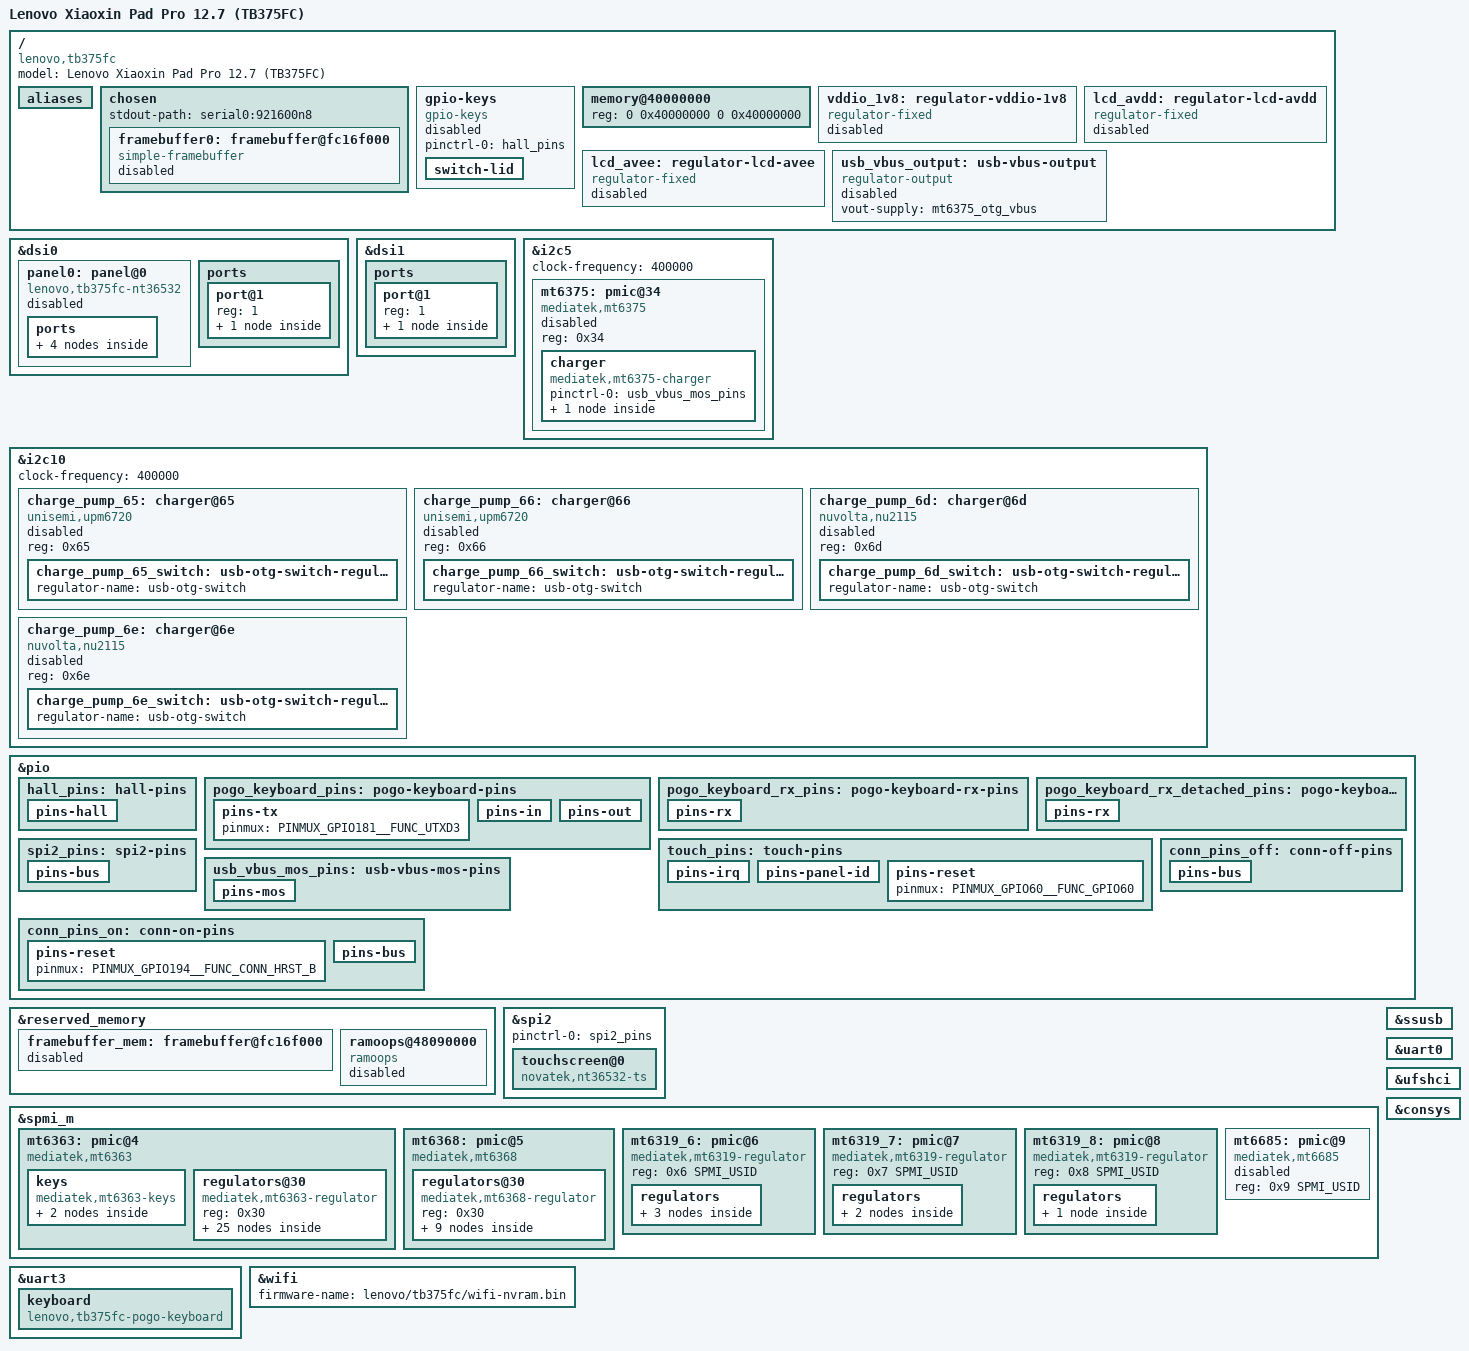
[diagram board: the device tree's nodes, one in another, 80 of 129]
// SPDX-License-Identifier: (GPL-2.0-only OR BSD-2-Clause)
/*
 * Lenovo Xiaoxin Pad Pro 12.7 (2025, TB375FC)
 *
 * Copyright (c) 2026 buntOS contributors
 */

/dts-v1/;
#include <dt-bindings/gpio/gpio.h>
#include <dt-bindings/input/input.h>
#include <dt-bindings/interrupt-controller/irq.h>
#include <dt-bindings/spmi/spmi.h>
#include "mt6897.dtsi"
#include "mt6897-pinfunc.h"

/ {
	model = "Lenovo Xiaoxin Pad Pro 12.7 (TB375FC)";
	compatible = "lenovo,tb375fc", "mediatek,mt6897";

	aliases {
		i2c5 = &i2c5;
		i2c10 = &i2c10;
		serial0 = &uart0;
		spmi0 = &spmi_m;
	};

	chosen {
		#address-cells = <2>;
		#size-cells = <2>;
		ranges;

		stdout-path = "serial0:921600n8";

		/*
		 * The bootloader drives the panel over both DSI links with DSC
		 * and scans out one 2944x1840 buffer. TODO(2a): the base is
		 * from the community port's bootloader log; confirm it on the
		 * device before enabling this and framebuffer_mem.
		 */
		framebuffer0: framebuffer@fc16f000 {
			compatible = "simple-framebuffer";
			reg = <0 0xfc16f000 0 (2944 * 1840 * 4)>;
			width = <2944>;
			height = <1840>;
			stride = <(2944 * 4)>;
			format = "a8r8g8b8";
			panel = <&panel0>;
			status = "disabled";
		};
	};

	/*
	 * Hall sensor. GPIO1 (stock hall_1) goes low when the cover closes
	 * over the screen. The stock hall_2 is the keyboard's plug-gpios, under
	 * &uart3. The tablet has no sensor for the keyboard folded back: the
	 * keyboard reports that itself, and its driver turns it into
	 * SW_TABLET_MODE.
	 * TODO(2c): enable with pio and check both levels with evtest.
	 */
	gpio-keys {
		compatible = "gpio-keys";
		pinctrl-names = "default";
		pinctrl-0 = <&hall_pins>;
		status = "disabled";

		switch-lid {
			label = "Lid";
			gpios = <&pio 1 GPIO_ACTIVE_LOW>;
			linux,input-type = <EV_SW>;
			linux,code = <SW_LID>;
			debounce-interval = <100>;
			wakeup-source;
		};
	};

	memory@40000000 {
		device_type = "memory";
		/* The bootloader fills in the real size (8 or 12 GiB) */
		reg = <0 0x40000000 0 0x40000000>;
	};

	/*
	 * The panel's 1.8 V I/O supply behind a switch on GPIO63 (stock
	 * vddio_1v8-gpios), which the touch side of the NT36532 shares. The
	 * bootloader turns it on with the panel, and nothing may turn it off
	 * while the display runs on simple-framebuffer. It stays on with the panel
	 * driver: stock turns it on before the DSI links and off after them, which
	 * the driver cannot do, and turns it on before it reads the panel ID strap.
	 * TODO(2c): enable with pio.
	 */
	vddio_1v8: regulator-vddio-1v8 {
		compatible = "regulator-fixed";
		regulator-name = "vddio_1v8";
		regulator-min-microvolt = <1800000>;
		regulator-max-microvolt = <1800000>;
		gpio = <&pio 63 GPIO_ACTIVE_HIGH>;
		enable-active-high;
		regulator-boot-on;
		regulator-always-on;
		status = "disabled";
	};

	/*
	 * The enables of the panel's bias chip, an SM5109 at 0x3e on i2c13 (stock
	 * bias_p-gpios and bias_n-gpios). The bootloader turns them on and writes
	 * 0x12 to its two voltage registers, and the stock kernel does too. Stock
	 * also waits 80 ms after the panel goes off. TODO(2c display): check that
	 * the chip keeps the voltages while off; else it needs a driver. 5.8 V is
	 * the value by the formula of the TPS65132, which has the same two
	 * registers; the SM5109's is not known.
	 */
	lcd_avdd: regulator-lcd-avdd {
		compatible = "regulator-fixed";
		regulator-name = "lcd_avdd";
		regulator-min-microvolt = <5800000>;
		regulator-max-microvolt = <5800000>;
		gpio = <&pio 187 GPIO_ACTIVE_HIGH>;
		enable-active-high;
		regulator-boot-on;
		off-on-delay-us = <80000>;
		status = "disabled";
	};

	lcd_avee: regulator-lcd-avee {
		compatible = "regulator-fixed";
		regulator-name = "lcd_avee";
		regulator-min-microvolt = <5800000>;
		regulator-max-microvolt = <5800000>;
		gpio = <&pio 186 GPIO_ACTIVE_HIGH>;
		enable-active-high;
		regulator-boot-on;
		off-on-delay-us = <80000>;
		status = "disabled";
	};

	/*
	 * Turns the USB VBUS boost on and off from user space, through the state
	 * attribute of this device, until the TCPC driver takes that over. Stays
	 * off with the MT6375 (see &i2c5).
	 */
	usb_vbus_output: usb-vbus-output {
		compatible = "regulator-output";
		vout-supply = <&mt6375_otg_vbus>;
		status = "disabled";
	};
};

/*
 * The tablet ships with one of three panels. The driver tells BOE from Tianma
 * by the strap on GPIO184, which the touchscreen reads as well; the two Tianma
 * panels take the same init sequence.
 *
 * The stock bootloader does not need these nodes to turn the display on, it has
 * its own device tree for that. On the way to the kernel it looks for
 * /soc/dsi/panel<n>/port/endpoint and logs a failure when it is not there.
 *
 * TODO(2c display): enable with the display pipeline, and take the panel
 * property off framebuffer0 at the same time: fw_devlink would hold simpledrm
 * back until the panel binds. Until then the display runs on simple-framebuffer.
 * The two LED drivers (SGM37604A at 0x36 on i2c13 and i2c3) have no driver yet.
 */
&dsi0 {
	panel0: panel@0 {
		compatible = "lenovo,tb375fc-nt36532", "novatek,nt36532";
		reg = <0>;
		width-mm = <273>;
		height-mm = <171>;
		reset-gpios = <&pio 41 GPIO_ACTIVE_LOW>;
		novatek,panel-id-gpios = <&pio 184 GPIO_ACTIVE_HIGH>;
		vddio-supply = <&vddio_1v8>;
		avdd-supply = <&lcd_avdd>;
		avee-supply = <&lcd_avee>;
		status = "disabled";

		ports {
			#address-cells = <1>;
			#size-cells = <0>;

			port@0 {
				reg = <0>;

				panel_in0: endpoint {
					remote-endpoint = <&dsi0_out>;
				};
			};

			port@1 {
				reg = <1>;

				panel_in1: endpoint {
					remote-endpoint = <&dsi1_out>;
				};
			};
		};
	};

	ports {
		#address-cells = <1>;
		#size-cells = <0>;

		port@1 {
			reg = <1>;

			dsi0_out: endpoint {
				remote-endpoint = <&panel_in0>;
			};
		};
	};
};

&dsi1 {
	ports {
		#address-cells = <1>;
		#size-cells = <0>;

		port@1 {
			reg = <1>;

			dsi1_out: endpoint {
				remote-endpoint = <&panel_in1>;
			};
		};
	};
};

/*
 * The MT6375 sources VBUS for USB host mode. Its boost feeds the connector
 * through the input FETs of the charge pump below, which stock closes first.
 *
 * TODO(USB host): stays off with &usb_vbus_output, &i2c5, &i2c10 and
 * &imp_iic_wrap_n/en until UFS root and the USB gadget work on the device. It
 * also needs &pio for its GPIO179 state. The stock tree has no pins and no pull
 * setting for these buses, and runs them at 1 MHz. Check with i2cdetect first,
 * reading only. There is no driver for the interrupt (GPIO7), the TCPC, the
 * charger, the fuel gauge or the ADCs yet.
 */
&i2c5 {
	clock-frequency = <400000>;

	mt6375: pmic@34 {
		compatible = "mediatek,mt6375";
		reg = <0x34>;
		status = "disabled";

		charger {
			compatible = "mediatek,mt6375-charger";
			pinctrl-names = "default";
			pinctrl-0 = <&usb_vbus_mos_pins>;

			mt6375_otg_vbus: usb-otg-vbus-regulator {
				regulator-name = "usb-otg-vbus";
				regulator-min-microvolt = <5000000>;
				regulator-max-microvolt = <5000000>;
				vbus-switch-supply = <&charge_pump_65_switch>;
			};
		};
	};
};

/*
 * The stock tree lists all of these and its drivers bind what answers: NU2115 at
 * 0x6d and 0x6e, or UPM6720 at 0x65 and 0x66. The one that stock names
 * primary_dvchg closes the FETs: the master at 0x6d or 0x65, or a chip strapped
 * as standalone. On the one tablet read so far, stock binds only the UPM6720 at
 * 0x65, so vbus-switch-supply above points at it. Other units may differ.
 *
 * TODO(USB host): on the device, see with i2cdetect which ones answer and which
 * is not strapped as a slave, and enable that one only.
 */
&i2c10 {
	clock-frequency = <400000>;

	charge_pump_65: charger@65 {
		compatible = "unisemi,upm6720";
		reg = <0x65>;
		status = "disabled";

		charge_pump_65_switch: usb-otg-switch-regulator {
			regulator-name = "usb-otg-switch";
		};
	};

	charge_pump_66: charger@66 {
		compatible = "unisemi,upm6720";
		reg = <0x66>;
		status = "disabled";

		charge_pump_66_switch: usb-otg-switch-regulator {
			regulator-name = "usb-otg-switch";
		};
	};

	charge_pump_6d: charger@6d {
		compatible = "nuvolta,nu2115";
		reg = <0x6d>;
		status = "disabled";

		charge_pump_6d_switch: usb-otg-switch-regulator {
			regulator-name = "usb-otg-switch";
		};
	};

	charge_pump_6e: charger@6e {
		compatible = "nuvolta,nu2115";
		reg = <0x6e>;
		status = "disabled";

		charge_pump_6e_switch: usb-otg-switch-regulator {
			regulator-name = "usb-otg-switch";
		};
	};
};

&pio {
	hall_pins: hall-pins {
		pins-hall {
			pinmux = <PINMUX_GPIO1__FUNC_GPIO1>;
			input-enable;
		};
	};

	/*
	 * The keyboard cover has one data wire on its pogo pins. UART3 TX drives
	 * it through a gate on GPIO71, and UART3 RX and GPIO40 listen to it.
	 * The stock driver leaves TX on the UART and bias on GPIO26 and GPIO40
	 * as the bootloader set it.
	 */
	pogo_keyboard_pins: pogo-keyboard-pins {
		pins-tx {
			pinmux = <PINMUX_GPIO181__FUNC_UTXD3>;
		};

		pins-in {
			pinmux = <PINMUX_GPIO26__FUNC_GPIO26>,
				 <PINMUX_GPIO40__FUNC_GPIO40>;
			input-enable;
		};

		pins-out {
			pinmux = <PINMUX_GPIO61__FUNC_GPIO61>,
				 <PINMUX_GPIO71__FUNC_GPIO71>;
		};
	};

	pogo_keyboard_rx_pins: pogo-keyboard-rx-pins {
		pins-rx {
			pinmux = <PINMUX_GPIO180__FUNC_URXD3>;
			input-enable;
		};
	};

	/* Nothing drives the wire without a keyboard, so RX leaves the UART */
	pogo_keyboard_rx_detached_pins: pogo-keyboard-rx-detached-pins {
		pins-rx {
			pinmux = <PINMUX_GPIO180__FUNC_GPIO180>;
			input-enable;
			bias-disable;
		};
	};

	/* The stock tree sets drive strength 2, which is 6 mA */
	spi2_pins: spi2-pins {
		pins-bus {
			pinmux = <PINMUX_GPIO11__FUNC_SPI2_CLK>,
				 <PINMUX_GPIO12__FUNC_SPI2_CSB>,
				 <PINMUX_GPIO13__FUNC_SPI2_MI>,
				 <PINMUX_GPIO14__FUNC_SPI2_MO>;
			drive-strength = <6>;
		};
	};

	touch_pins: touch-pins {
		pins-irq {
			pinmux = <PINMUX_GPIO9__FUNC_GPIO9>;
			input-enable;
		};

		pins-panel-id {
			pinmux = <PINMUX_GPIO184__FUNC_GPIO184>;
			input-enable;
		};

		pins-reset {
			pinmux = <PINMUX_GPIO60__FUNC_GPIO60>;
		};
	};

	/*
	 * GPIO179 (stock vbus_mos_gpio) is the over-temperature protection of USB
	 * VBUS. Stock drives it low from its charger probe on and, with a charger
	 * attached, raises it above 75 degrees on the usb_board_ntc sensor, which
	 * has no driver here yet.
	 */
	usb_vbus_mos_pins: usb-vbus-mos-pins {
		pins-mos {
			pinmux = <PINMUX_GPIO179__FUNC_GPIO179>;
			output-low;
		};
	};

	/*
	 * The interface of the RF chip. The driver also switches the pull of
	 * GPIO193 and GPIO202, which the stock kernel does without touching
	 * their pull resistor selection.
	 */
	conn_pins_off: conn-off-pins {
		pins-bus {
			pinmux = <PINMUX_GPIO192__FUNC_GPIO192>,
				 <PINMUX_GPIO193__FUNC_GPIO193>,
				 <PINMUX_GPIO194__FUNC_GPIO194>,
				 <PINMUX_GPIO195__FUNC_GPIO195>,
				 <PINMUX_GPIO196__FUNC_GPIO196>,
				 <PINMUX_GPIO197__FUNC_GPIO197>,
				 <PINMUX_GPIO198__FUNC_GPIO198>,
				 <PINMUX_GPIO199__FUNC_GPIO199>,
				 <PINMUX_GPIO200__FUNC_GPIO200>,
				 <PINMUX_GPIO201__FUNC_GPIO201>,
				 <PINMUX_GPIO202__FUNC_GPIO202>;
		};
	};

	conn_pins_on: conn-on-pins {
		pins-reset {
			pinmux = <PINMUX_GPIO194__FUNC_CONN_HRST_B>;
		};

		pins-bus {
			pinmux = <PINMUX_GPIO192__FUNC_CONN_TOP_CLK>,
				 <PINMUX_GPIO193__FUNC_CONN_TOP_DATA>,
				 <PINMUX_GPIO195__FUNC_CONN_WF_CTRL0>,
				 <PINMUX_GPIO196__FUNC_CONN_WF_CTRL1>,
				 <PINMUX_GPIO197__FUNC_CONN_WF_CTRL2>,
				 <PINMUX_GPIO198__FUNC_CONN_WF_CTRL3>,
				 <PINMUX_GPIO199__FUNC_CONN_WF_CTRL4>,
				 <PINMUX_GPIO200__FUNC_CONN_WB_PTA>,
				 <PINMUX_GPIO201__FUNC_CONN_BT_CLK>,
				 <PINMUX_GPIO202__FUNC_CONN_BT_DATA>;
			drive-strength = <4>;
		};
	};
};

&reserved_memory {
	/* The bootloader's three-buffer allocation behind framebuffer0 */
	framebuffer_mem: framebuffer@fc16f000 {
		reg = <0 0xfc16f000 0 0x3e90000>;
		no-map;
		status = "disabled";
	};

	/* TODO(2a): confirm this gap survives warm reboots, then enable */
	ramoops@48090000 {
		compatible = "ramoops";
		reg = <0 0x48090000 0 0xe0000>;
		record-size = <0x20000>;
		console-size = <0x40000>;
		pmsg-size = <0x80000>;
		status = "disabled";
	};
};

/* TODO(2c): spi2 stays disabled (mt6897.dtsi) until pio and the clocks are on */
&spi2 {
	pinctrl-names = "default";
	pinctrl-0 = <&spi2_pins>;

	/*
	 * The touch and stylus side of the NT36532 TDDI. The firmware is tuned
	 * per panel: the panel ID strap on GPIO184 reads 0 with the BOE panel
	 * and 1 with the two Tianma panels. The controller's X runs along the
	 * 1840-pixel side and Y along the 2944-pixel side, both in tenths of a
	 * pixel and up to 18400 and 29440, while the panel scans out
	 * 2944x1840. The active area is 273.6 x 171.0 mm (12.7", 16:10).
	 * TODO(2c): check the direction of both axes with evtest and add
	 * touchscreen-inverted-x/y where needed.
	 */
	touchscreen@0 {
		compatible = "novatek,nt36532-ts";
		reg = <0>;
		spi-max-frequency = <9600000>;
		interrupts-extended = <&pio 9 IRQ_TYPE_EDGE_RISING>;
		reset-gpios = <&pio 60 GPIO_ACTIVE_LOW>;
		iovcc-supply = <&vddio_1v8>;
		pinctrl-names = "default";
		pinctrl-0 = <&touch_pins>;
		firmware-name = "lenovo/tb375fc/novatek_ts_fw_boe.bin",
				"lenovo/tb375fc/novatek_ts_fw_tm.bin";
		novatek,panel-id-gpios = <&pio 184 GPIO_ACTIVE_HIGH>;
		touchscreen-size-x = <18401>;
		touchscreen-size-y = <29441>;
		touchscreen-x-mm = <171>;
		touchscreen-y-mm = <273>;
		touchscreen-swapped-x-y;
	};
};

&spmi_m {
	/*
	 * MT6363 main PMIC. The key interrupts are those of the stock
	 * driver's PSC group: PWRKEY 48, HOMEKEY 49, PWRKEY_R 51 and
	 * HOMEKEY_R 52. The stock tree uses HOMEKEY as volume up and resets
	 * on a long press of both keys.
	 */
	mt6363: pmic@4 {
		compatible = "mediatek,mt6363";
		reg = <0x4 SPMI_USID>;
		interrupts = <0x4 64 IRQ_TYPE_LEVEL_HIGH>;
		interrupt-controller;
		#interrupt-cells = <3>;
		#address-cells = <1>;
		#size-cells = <0>;

		keys {
			compatible = "mediatek,mt6363-keys";
			mediatek,long-press-mode = <2>;
			power-off-time-sec = <0>;

			power-key {
				interrupts = <0x4 48 IRQ_TYPE_LEVEL_HIGH>,
					     <0x4 51 IRQ_TYPE_LEVEL_HIGH>;
				interrupt-names = "powerkey", "powerkey_r";
				linux,keycodes = <KEY_POWER>;
				wakeup-source;
			};

			home-key {
				interrupts = <0x4 49 IRQ_TYPE_LEVEL_HIGH>,
					     <0x4 52 IRQ_TYPE_LEVEL_HIGH>;
				interrupt-names = "homekey", "homekey_r";
				linux,keycodes = <KEY_VOLUMEUP>;
			};
		};

		/*
		 * The rails the stock tree keeps on, and VEMC for UFS. The
		 * stock tree turns the others (vbuck1, vbuck3, vbuck7, vcn13,
		 * vcn15, vrf*, vsram-digrf) on for the modem, RF and
		 * connectivity when they need them; leaving them out of this
		 * node keeps Linux from touching them. Nothing sets a voltage
		 * yet, so no limits are given and the core keeps what the
		 * bootloader set. Names come from the stock consumers where
		 * there is one: dvfsrc (vcore), the GPU SRAM, the modem and UFS.
		 */
		regulators@30 {
			compatible = "mediatek,mt6363-regulator";
			reg = <0x30>;

			mt6363_va12_1: va12-1 {
				regulator-name = "mt6363_va12_1";
				regulator-enable-ramp-delay = <180>;
				regulator-always-on;
			};

			mt6363_va12_2: va12-2 {
				regulator-name = "mt6363_va12_2";
				regulator-enable-ramp-delay = <180>;
				regulator-always-on;
			};

			mt6363_va15: va15 {
				regulator-name = "mt6363_va15";
				regulator-enable-ramp-delay = <180>;
				regulator-always-on;
			};

			mt6363_vaux18: vaux18 {
				regulator-name = "mt6363_vaux18";
				regulator-enable-ramp-delay = <240>;
				regulator-always-on;
			};

			mt6363_vbuck2: vbuck2 {
				regulator-name = "vmodem";
				regulator-enable-ramp-delay = <200>;
				regulator-always-on;
			};

			mt6363_vbuck4: vbuck4 {
				regulator-name = "mt6363_vbuck4";
				regulator-enable-ramp-delay = <200>;
				regulator-always-on;
			};

			mt6363_vbuck5: vbuck5 {
				regulator-name = "mt6363_vbuck5";
				regulator-enable-ramp-delay = <200>;
				regulator-always-on;
			};

			mt6363_vbuck6: vbuck6 {
				regulator-name = "vcore";
				regulator-enable-ramp-delay = <300>;
				regulator-always-on;
			};

			/*
			 * Disabled rails stay as they are, like the ones left out
			 * of this node. They wait for the connectivity bring-up.
			 */
			mt6363_vcn13: vcn13 {
				regulator-name = "mt6363_vcn13";
				regulator-min-microvolt = <1350000>;
				regulator-max-microvolt = <1350000>;
				regulator-enable-ramp-delay = <180>;
				regulator-allowed-modes = <0 2>;
				status = "disabled";
			};

			mt6363_vemc: vemc {
				regulator-name = "vufs_vcc";
				regulator-enable-ramp-delay = <680>;
			};

			mt6363_vio0p75: vio0p75 {
				regulator-name = "mt6363_vio0p75";
				regulator-enable-ramp-delay = <3000>;
				regulator-always-on;
			};

			mt6363_vio18: vio18 {
				regulator-name = "vio18";
				regulator-enable-ramp-delay = <680>;
				regulator-always-on;
			};

			mt6363_vm18: vm18 {
				regulator-name = "mt6363_vm18";
				regulator-enable-ramp-delay = <280>;
				regulator-always-on;
			};

			/* Feeds the 1.8 V side of the RF chip, at 1.7 V as the stock driver does */
			mt6363_vrfio18: vrf-io18 {
				regulator-name = "mt6363_vrfio18";
				regulator-min-microvolt = <1700000>;
				regulator-max-microvolt = <1700000>;
				regulator-enable-ramp-delay = <180>;
				regulator-allowed-modes = <0 2>;
				status = "disabled";
			};

			mt6363_vs1: vs1 {
				regulator-name = "mt6363_vs1";
				regulator-enable-ramp-delay = <180>;
				regulator-always-on;
			};

			mt6363_vs2: vs2 {
				regulator-name = "mt6363_vs2";
				regulator-enable-ramp-delay = <180>;
				regulator-always-on;
			};

			mt6363_vs3: vs3 {
				regulator-name = "mt6363_vs3";
				regulator-enable-ramp-delay = <180>;
				regulator-always-on;
			};

			mt6363_vsram_cpub: vsram-cpub {
				regulator-name = "mt6363_vsram_cpub";
				regulator-enable-ramp-delay = <180>;
				regulator-always-on;
			};

			mt6363_vsram_cpul: vsram-cpul {
				regulator-name = "mt6363_vsram_cpul";
				regulator-enable-ramp-delay = <180>;
				regulator-always-on;
			};

			mt6363_vsram_cpum: vsram-cpum {
				regulator-name = "mt6363_vsram_cpum";
				regulator-enable-ramp-delay = <180>;
				regulator-always-on;
			};

			mt6363_vsram_mdfe: vsram-mdfe {
				regulator-name = "vsram_gpu";
				regulator-enable-ramp-delay = <180>;
				regulator-always-on;
			};

			mt6363_vsram_modem: vsram-modem {
				regulator-name = "vsram_modem";
				regulator-enable-ramp-delay = <180>;
				regulator-always-on;
			};

			mt6363_vtref18: vtref18 {
				regulator-name = "mt6363_vtref18";
				regulator-enable-ramp-delay = <240>;
				regulator-always-on;
			};

			mt6363_vufs12: vufs12 {
				regulator-name = "mt6363_vufs12";
				regulator-enable-ramp-delay = <280>;
				regulator-always-on;
			};

			mt6363_vufs18: vufs18 {
				regulator-name = "mt6363_vufs18";
				regulator-enable-ramp-delay = <680>;
				regulator-always-on;
			};
		};
	};

	/*
	 * MT6368 second PMIC, with the rails the stock tree keeps on: among
	 * them USB's analog supply and the GPU core, which stays on until a
	 * GPU driver takes it. The stock tree leaves the others to their
	 * users, such as vibr (the vibrator and the camera autofocus), vfp
	 * (the fingerprint sensor), vaud18 (the audio codec), vmc and
	 * vmch-eint-* (the SD card) and vsim2 (the cameras); leaving them
	 * out of this node keeps Linux from touching them. As on the MT6363,
	 * no voltage limits are given and the names come from the stock
	 * consumers where there is one.
	 */
	mt6368: pmic@5 {
		compatible = "mediatek,mt6368";
		reg = <0x5 SPMI_USID>;
		interrupts = <0x5 48 IRQ_TYPE_LEVEL_HIGH>;
		interrupt-controller;
		#interrupt-cells = <3>;
		#address-cells = <1>;
		#size-cells = <0>;

		regulators@30 {
			compatible = "mediatek,mt6368-regulator";
			reg = <0x30>;

			mt6368_vant18: vant18 {
				regulator-name = "mt6368_vant18";
				regulator-enable-ramp-delay = <680>;
				regulator-allowed-modes = <0 2>;
				status = "disabled";
			};

			mt6368_vbuck2: vbuck2 {
				regulator-name = "vgpu";
				regulator-enable-ramp-delay = <200>;
				regulator-always-on;
			};

			mt6368_vbuck5: vbuck5 {
				regulator-name = "mt6368_vbuck5";
				regulator-enable-ramp-delay = <180>;
				regulator-always-on;
			};

			mt6368_vbuck6: vbuck6 {
				regulator-name = "mt6368_vbuck6";
				regulator-enable-ramp-delay = <180>;
				regulator-always-on;
			};

			mt6368_vcn33_1: vcn33-1 {
				regulator-name = "mt6368_vcn33_1";
				regulator-enable-ramp-delay = <680>;
				regulator-allowed-modes = <0 2>;
				status = "disabled";
			};

			mt6368_vcn33_2: vcn33-2 {
				regulator-name = "mt6368_vcn33_2";
				regulator-enable-ramp-delay = <680>;
				regulator-allowed-modes = <0 2>;
				status = "disabled";
			};

			mt6368_vio28: vio28 {
				regulator-name = "mt6368_vio28";
				regulator-enable-ramp-delay = <680>;
				regulator-always-on;
			};

			mt6368_vtp: vtp {
				regulator-name = "mt6368_vtp";
				regulator-enable-ramp-delay = <680>;
				regulator-always-on;
			};

			mt6368_vusb: vusb {
				regulator-name = "vusb33";
				regulator-enable-ramp-delay = <680>;
				regulator-always-on;
			};
		};
	};

	/*
	 * MT6319 buck PMICs, as in the stock tree. Their users there:
	 * 6/vbuck1 the ISP and camera power domains, 6/vbuck3 (proc1 and
	 * proc4), 7/vbuck1 (proc2) and 6/vbuck4 (proc3) the CPU DVFS that
	 * the MCUPM drives, 8/vbuck3 UFS VCCQ; 7/vbuck3 has none. Buck 2 is
	 * paired with buck 1 on all three. UFS takes 8/vbuck3 here too, and
	 * nothing claims the others yet, so all of them stay on through the
	 * unused regulator cleanup. The driver picks the paired bucks by SID
	 * as on MT8195 boards, which does not match this board, so no
	 * operating modes are allowed.
	 */
	mt6319_6: pmic@6 {
		compatible = "mediatek,mt6319-regulator", "mediatek,mt6315-regulator";
		reg = <0x6 SPMI_USID>;

		regulators {
			mt6319_6_vbuck1: vbuck1 {
				regulator-name = "vmm";
				regulator-min-microvolt = <300000>;
				regulator-max-microvolt = <1193750>;
				regulator-enable-ramp-delay = <256>;
				regulator-always-on;
			};

			mt6319_6_vbuck3: vbuck3 {
				regulator-name = "vproc1";
				regulator-min-microvolt = <300000>;
				regulator-max-microvolt = <1193750>;
				regulator-enable-ramp-delay = <256>;
				regulator-always-on;
			};

			mt6319_6_vbuck4: vbuck4 {
				regulator-name = "vproc3";
				regulator-min-microvolt = <300000>;
				regulator-max-microvolt = <1193750>;
				regulator-enable-ramp-delay = <256>;
				regulator-always-on;
			};
		};
	};

	mt6319_7: pmic@7 {
		compatible = "mediatek,mt6319-regulator", "mediatek,mt6315-regulator";
		reg = <0x7 SPMI_USID>;

		regulators {
			mt6319_7_vbuck1: vbuck1 {
				regulator-name = "vproc2";
				regulator-min-microvolt = <300000>;
				regulator-max-microvolt = <1193750>;
				regulator-enable-ramp-delay = <256>;
				regulator-always-on;
			};

			mt6319_7_vbuck3: vbuck3 {
				regulator-name = "mt6319_7_vbuck3";
				regulator-min-microvolt = <300000>;
				regulator-max-microvolt = <1193750>;
				regulator-enable-ramp-delay = <256>;
				regulator-always-on;
			};
		};
	};

	mt6319_8: pmic@8 {
		compatible = "mediatek,mt6319-regulator", "mediatek,mt6315-regulator";
		reg = <0x8 SPMI_USID>;

		regulators {
			mt6319_8_vbuck3: vbuck3 {
				regulator-name = "vufs_vccq";
				regulator-min-microvolt = <300000>;
				regulator-max-microvolt = <1193750>;
				regulator-enable-ramp-delay = <256>;
				regulator-always-on;
			};
		};
	};

	/*
	 * Clock buffer, RTC and more. It has no driver; the connectivity driver
	 * reads the frequency of the RF chip's clock from it.
	 * TODO(2d): enable with consys.
	 */
	mt6685: pmic@9 {
		compatible = "mediatek,mt6685";
		reg = <0x9 SPMI_USID>;
		status = "disabled";
	};
};

/*
 * USB's analog supply, as in the stock tree. The stock controller is dual role,
 * but this starts as a USB device only, because the USB gadget is the way into
 * the tablet while it is being brought up.
 *
 * TODO(USB host): once UFS root and the gadget work on the device, and the
 * nodes under &i2c5 and &i2c10 are on, enable &xhci0 and add
 *
 *	dr_mode = "otg";
 *	usb-role-switch;
 *	role-switch-default-mode = "peripheral";
 *
 * The role is then in /sys/class/usb_role/11201000.usb-role-switch/role and VBUS
 * in the state attribute of &usb_vbus_output. Without the TCPC nothing does this
 * by itself. Never add vbus-supply here: in otg mode ssusb_host_setup() enables
 * it at every probe, whatever is on the port.
 */
&ssusb {
	dr_mode = "peripheral";
	vusb33-supply = <&mt6368_vusb>;
};

/* Debug UART, GPIO207 (TX) and GPIO208 (RX) */
&uart0 {
	status = "okay";
};

/*
 * TODO(2c): uart3 stays disabled (mt6897.dtsi) until pio and the clock
 * controllers are on. Then check the attach and detach levels of GPIO26, that
 * the first frames decode, and what the keyboard sends when folded back.
 */
&uart3 {
	/*
	 * The keyboard cover. GPIO61 switches its supply, GPIO26 (stock hall_2)
	 * goes low when a keyboard is attached and GPIO40 wakes the system when
	 * a sleeping keyboard starts to send.
	 */
	keyboard {
		compatible = "lenovo,tb375fc-pogo-keyboard";
		power-gpios = <&pio 61 GPIO_ACTIVE_HIGH>;
		tx-enable-gpios = <&pio 71 GPIO_ACTIVE_HIGH>;
		wake-gpios = <&pio 40 GPIO_ACTIVE_HIGH>;
		plug-gpios = <&pio 26 GPIO_ACTIVE_LOW>;
		pinctrl-names = "default", "detached";
		pinctrl-0 = <&pogo_keyboard_pins>, <&pogo_keyboard_rx_pins>;
		pinctrl-1 = <&pogo_keyboard_pins>, <&pogo_keyboard_rx_detached_pins>;
		wakeup-source;
	};
};

/* UFS supplies, as in the stock tree */
&ufshci {
	vcc-supply = <&mt6363_vemc>;
	vccq-supply = <&mt6319_8_vbuck3>;
};

&consys {
	vcn13-supply = <&mt6363_vcn13>;
	vrfio18-supply = <&mt6363_vrfio18>;
	vcn33-1-supply = <&mt6368_vcn33_1>;
	vcn33-2-supply = <&mt6368_vcn33_2>;
	vant18-supply = <&mt6368_vant18>;
	mediatek,dcxo = <&mt6685>;
	pinctrl-names = "default", "active";
	pinctrl-0 = <&conn_pins_off>;
	pinctrl-1 = <&conn_pins_on>;
};

/*
 * The stock tree picks the RF front end by a hardware ID property it does not
 * have, which makes it none, unless a file on the device says otherwise. Leaving
 * out mediatek,fem-parts says none. TODO(2d): compare with the "FemInfo" line of
 * the stock driver's log.
 */
&wifi {
	firmware-name = "lenovo/tb375fc/wifi-nvram.bin";
};
